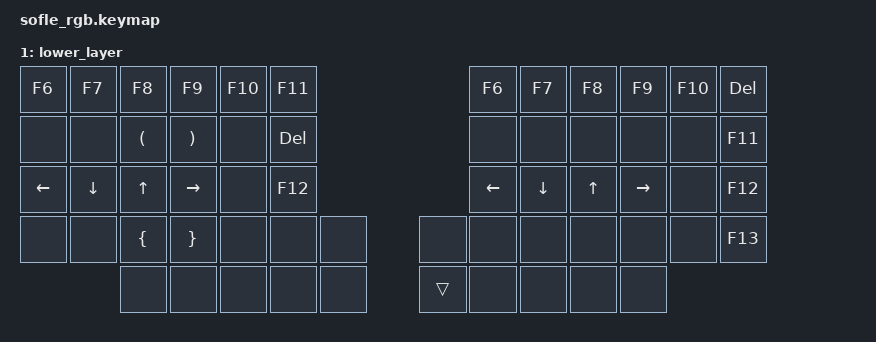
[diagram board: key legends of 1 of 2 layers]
#include <behaviors.dtsi>
#include <dt-bindings/zmk/keys.h>
#include <dt-bindings/zmk/bt.h>
#include <dt-bindings/zmk/outputs.h>

/ {
  keymap {
    compatible = "zmk,keymap";

    default_layer {
      bindings = <
        &kp N6        &kp N7   &kp N8    &kp N9    &kp N0    &kp BACKSLASH                          &kp N6  &kp N7   &kp N8    &kp N9  &kp N0    &kp BACKSPACE
        &kp Y         &kp U    &kp I     &kp O     &kp P     &kp BACKSPACE                           &kp Y   &kp U    &kp I     &kp O   &kp P     &kp BACKSLASH
        &kp H         &kp J    &kp K     &kp L     &kp SEMI  &kp SINGLE_QUOTE                           &kp H   &kp J    &kp K     &kp L   &kp SEMI  &kp SINGLE_QUOTE
        &kp N         &kp M    &kp COMMA     &kp DOT     &kp SLASH     &kp RSHIFT     &kp K_PP &out OUT_TOG &kp N   &kp M    &kp COMMA &kp DOT &kp SLASH &mt RSHIFT RPAR
                                 &mo 1    &kp RET  &kp EQUAL &kp RALT &kp RGUI        &kp RET &kp RBKT &kp EQUAL &kp ESC
      >;

      sensor-bindings = <&inc_dec_kp C_VOL_UP C_VOL_DN &inc_dec_kp PG_UP PG_DN>;
    };

    lower_layer {
      bindings = <
        &kp F6    &kp F7     &kp F8      &kp F9       &kp F10   &kp F11             &kp F6    &kp F7     &kp F8  &kp F9    &kp F10 &kp DELETE
        &none     &none      &kp LPAR    &kp RPAR     &none     &kp DELETE              &none     &none      &none   &none     &none   &kp F11
        &kp LEFT  &kp DOWN   &kp UP      &kp RIGHT    &none     &kp F12              &kp LEFT  &kp DOWN   &kp UP  &kp RIGHT &none   &kp F12
        &none     &none      &kp LBRC    &kp RBRC     &none     &none                  &none &none  &none     &none      &none   &none     &none   &kp F13
                         &none       &none        &none  &none &none &trans &none     &none      &none   &none
      >;

      sensor-bindings = <&inc_dec_kp C_VOL_UP C_VOL_DN &inc_dec_kp PG_UP PG_DN>;
    };

  };
};

// layer sample
//         &none &none &none &none &none &none             &none &none &none &none &none &none
//         &none &none &none &none &none &none             &none &none &none &none &none &none
//         &none &none &none &none &none &none             &none &none &none &none &none &none
//         &none &none &none &none &none &none &none &none &none &none &none &none &none &none
//                     &none &none &none &none &none &none &none &none &none &none
